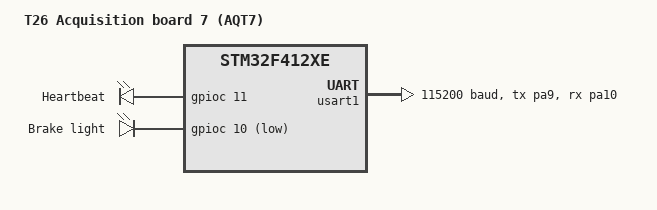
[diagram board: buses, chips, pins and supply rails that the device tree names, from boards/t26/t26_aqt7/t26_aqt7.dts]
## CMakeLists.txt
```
cmake_minimum_required(VERSION 3.20.0)

# The t26_aqt7 board lives in this folder (boards/t26/t26_aqt7).
# Zephyr doesn't search the application folder for boards on its own, so add it here.
list(APPEND BOARD_ROOT ${CMAKE_CURRENT_SOURCE_DIR})

# Default board when none is given (west build without -b, CLion "Let CMake decide").
# The board isn't in Zephyr's own board list, so IDE board pickers don't show it.
# A -b / BOARD given on the command line still takes precedence.
set(BOARD t26_aqt7 CACHE STRING "Zephyr board")

find_package(Zephyr REQUIRED HINTS $ENV{ZEPHYR_BASE})
project(t26_aqt7)

# Repository root: shared code used by both the STM32CubeIDE and the Zephyr builds
set(REPO_DIR ${CMAKE_CURRENT_SOURCE_DIR}/..)

target_sources(app PRIVATE
  src/main.c
  src/conversions.c
  src/sensors.c
  src/brake_light.c
  src/can_bus.c
  src/can_rx.c
  src/can_tx.c
  src/watchdog.c
  src/debug.c
  # cantools output, updated by the DBC workflow: never edit, only reference
  ${REPO_DIR}/Core/DBC/data_t26.c
  ${REPO_DIR}/Core/DBC/autonomous_t26.c
)

# "sim" shell command (CONFIG_AQT7_SIM, on by default when the shell is on)
target_sources_ifdef(CONFIG_AQT7_SIM app PRIVATE src/sim.c)

target_include_directories(app PRIVATE
  ${REPO_DIR}/Core/DBC
)
```

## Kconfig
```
# Application options for the AQT7 firmware. Set them in prj.conf.

mainmenu "T26 AQT7"

config AQT7_DEBUG_PRINT_MS
	int "Period of the sensor values log (ms), 0 = off"
	default 100
	help
	  The debug thread logs the brake pressures, suspensions and NTC with
	  their ADC values on the console every this many milliseconds, like
	  execute_100ms_tasks() in the STM32CubeIDE firmware. 0 turns it off;
	  the acq7 debug snapshot is updated either way.

source "Kconfig.zephyr"
```

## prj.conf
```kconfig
# GPIO: heartbeat (PC11) and brake light (PC10)
CONFIG_GPIO=y

# ADC1 (brake pressure, suspension, NTC) and CAN1/CAN2 drivers
CONFIG_ADC=y
CONFIG_CAN=y
# Error counters per type (stuff, form, ACK, bit, CRC) for can_bus_service()
CONFIG_STATS=y
CONFIG_CAN_STATS=y

# IWDG (watchdog0)
CONFIG_WATCHDOG=y
# sys_reboot(), used if a module fails to start and the IWDG isn't running
CONFIG_REBOOT=y

# Logging over the console (USART1, 115200 8N1)
CONFIG_LOG=y
CONFIG_LOG_DEFAULT_LEVEL=3
# %f in LOG_* / printk (sensor values in bar, mm, C)
CONFIG_CBPRINTF_FP_SUPPORT=y

# Use the Cortex-M4F hardware FPU for the sensor maths
CONFIG_FPU=y

# Sensor values log period (ms), like the CubeIDE 100 ms printf. 0 = off (acq7 still updated)
CONFIG_AQT7_DEBUG_PRINT_MS=100
```

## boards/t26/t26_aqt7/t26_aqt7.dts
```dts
/*
 * T26 Acquisition board 7 (AQT7)
 * MCU: STM32F412RET6 (512 KB Flash, 256 KB RAM, LQFP64)
 *
 * Pins and clocks follow T26_Acquisition_7.ioc (read-only reference).
 * Only clocks, console and the two outputs are described so far.
 * ADC1, CAN1, CAN2 and IWDG are added as they are ported.
 */

/dts-v1/;
#include <st/f4/stm32f412Xe.dtsi>
#include <st/f4/stm32f412r(e-g)tx-pinctrl.dtsi>

/ {
	model = "T26 Acquisition board 7 (AQT7)";
	compatible = "t26,aqt7";

	chosen {
		zephyr,console = &usart1;
		zephyr,shell-uart = &usart1;
		zephyr,sram = &sram0;
		zephyr,flash = &flash0;
	};

	leds: leds {
		compatible = "gpio-leds";

		/* PC11, toggled by the firmware to show the main loop is alive */
		heartbeat: heartbeat {
			gpios = <&gpioc 11 GPIO_ACTIVE_HIGH>;
			label = "Heartbeat";
		};

		/* PC10, active low: the pin is driven LOW to turn the brake light on.
		 * With GPIO_ACTIVE_LOW, gpio_pin_set_dt(..., 1) means "light on".
		 */
		brake_light: brake_light {
			gpios = <&gpioc 10 GPIO_ACTIVE_LOW>;
			label = "Brake light";
		};
	};

	aliases {
		led0 = &heartbeat;	/* lets samples/basic/blinky run unmodified */
		heartbeat = &heartbeat;
		brake-light = &brake_light;
	};
};

/* LSI: clock for the IWDG (watchdog), to be enabled when it is ported */
&clk_lsi {
	status = "okay";
};

/* No crystal on the board: HSI 16 MHz, same as the CubeIDE firmware */
&clk_hsi {
	status = "okay";
};

/* 16 MHz / 8 * 96 = 192 MHz VCO, /2 = 96 MHz SYSCLK, /4 = 48 MHz (Q, unused) */
&pll {
	div-m = <8>;
	mul-n = <96>;
	div-p = <2>;
	div-q = <4>;
	clocks = <&clk_hsi>;
	status = "okay";
};

/* SYSCLK 96 MHz, APB1 48 MHz (CAN), APB2 96 MHz (ADC, USART1) */
&rcc {
	clocks = <&pll>;
	clock-frequency = <DT_FREQ_M(96)>;
	ahb-prescaler = <1>;
	apb1-prescaler = <2>;
	apb2-prescaler = <1>;
};

&usart1 {
	pinctrl-0 = <&usart1_tx_pa9 &usart1_rx_pa10>;
	pinctrl-names = "default";
	current-speed = <115200>;
	status = "okay";
};
```

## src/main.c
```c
/*
 * T26 Acquisition board 7 (AQT7), Zephyr port.
 * Based on "original" C code
 *
 * main starts the IWDG, sets up the hardware in order, starts each module's thread, then runs
 * the heartbeat and feeds the watchdog while every thread is alive.
 *
 * Every module is required, like in the CubeIDE firmware: if one fails to set up, watchdog_fail()
 * stops feeding and the board resets after 2 s and tries the whole setup again
 * (the CubeIDE firmware did the same through Error_Handler + IWDG).
 */

#include <zephyr/kernel.h>
#include <zephyr/drivers/gpio.h>
#include <zephyr/logging/log.h>

#include "brake_light.h"
#include "can_bus.h"
#include "can_rx.h"
#include "can_tx.h"
#include "debug.h"
#include "sensors.h"
#include "watchdog.h"

LOG_MODULE_REGISTER(aqt7, LOG_LEVEL_INF);

#define HEARTBEAT_PERIOD_MS 100

static const struct gpio_dt_spec heartbeat = GPIO_DT_SPEC_GET(DT_ALIAS(heartbeat), gpios);

int main(void) {
    LOG_INF("T26 AQT7 starting on %s", CONFIG_BOARD);

    /* First, so a hang anywhere in the setup below also resets the board.
     * If it fails the board still runs, unprotected: that is better than not running at all.
     */
    if (watchdog_init() < 0) {
        LOG_ERR("IWDG not running: the board will NOT reset on a hang");
    }

    if (!gpio_is_ready_dt(&heartbeat) || gpio_pin_configure_dt(&heartbeat, GPIO_OUTPUT_INACTIVE) < 0) {
        watchdog_fail("heartbeat GPIO setup failed");
    }

    // ADC1: brake pressure, suspension, NTC
    if (sensors_init() < 0) {
        watchdog_fail("ADC setup failed");
    }

    // PC10 brake light
    if (brake_light_init() < 0) {
        watchdog_fail("brake light setup failed");
    }

    // Both CAN buses: start + RX filters
    if (can_bus_init(can_rx_ids, can_rx_id_count) < 0) {
        watchdog_fail("CAN setup failed");
    }

    // All hardware ready: start the threads (each registers with the watchdog)
    sensors_start();
    brake_light_start();
    can_rx_start();
    can_tx_start();
    debug_start();

    /* Absolute deadlines: the period doesn't drift with the time spent in the loop */
    int64_t next = k_uptime_get();

    while (1) {
        gpio_pin_toggle_dt(&heartbeat);
        watchdog_service();
        can_bus_service(); /* bus health, error log, restart of a stopped controller */

        next += HEARTBEAT_PERIOD_MS;
        k_sleep(K_TIMEOUT_ABS_MS(next));
    }

    return 0;
}
```

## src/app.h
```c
/*
 * Application-wide settings shared by the modules.
 */

#ifndef T26_AQT7_APP_H_
#define T26_AQT7_APP_H_

/*
 * Thread priorities: lower number = runs first (all preemptible).
 * Every thread is defined with SYS_FOREVER_MS as start delay, so it is created at boot but only
 * runs once main calls its module's *_start(), after the hardware it needs is set up.
 */
#define PRIO_SENSORS     2
#define PRIO_BRAKE_LIGHT 3
#define PRIO_CAN_RX      4
#define PRIO_CAN_TX      5
#define PRIO_DEBUG       6  /* lowest: snapshot and log only use spare CPU time */

#define STACK_SIZE_DEFAULT 1024
#define STACK_SIZE_DEBUG   2048 /* float formatting in the log */

#endif /* T26_AQT7_APP_H_ */
```

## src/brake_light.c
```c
/*
 * Brake light: PC10, driven from the rear (ADC) and front (CAN1 0x710) brake pressures.
 */

#include <zephyr/kernel.h>
#include <zephyr/drivers/gpio.h>
#include <zephyr/logging/log.h>

#include "app.h"
#include "watchdog.h"
#include "brake_light.h"
#include "can_rx.h"
#include "sensors.h"

LOG_MODULE_REGISTER(brake_light, LOG_LEVEL_INF);

#define BRAKE_LIGHT_PERIOD_MS 50
#define PRESSURE_LEVEL_REAR 7
#define PRESSURE_LEVEL_FRONT 7

static const struct gpio_dt_spec brake_light = GPIO_DT_SPEC_GET(DT_ALIAS(brake_light), gpios);

int brake_light_init(void) {
    if (!gpio_is_ready_dt(&brake_light)) {
        LOG_ERR("Brake light GPIO not ready");
        return -ENODEV;
    }

    /* Inactive = light off. The pin is active low in the devicetree, so this drives PC10 HIGH.
     * (The CubeIDE firmware boots with PC10 LOW, i.e. light on until the first 50 ms task.)
     */
    return gpio_pin_configure_dt(&brake_light, GPIO_OUTPUT_INACTIVE);
}

/**
 * Brake Light Thread
 * @param p1 UNUSED
 * @param p2 UNUSED
 * @param p3 UNUSED
 */
static void brake_light_thread(void *p1, void *p2, void *p3) {
    ARG_UNUSED(p1);
    ARG_UNUSED(p2);
    ARG_UNUSED(p3);

    while (1) {
        watchdog_checkin(WDOG_BRAKE_LIGHT);

        bool is_on = sensors_get().rear_brake_bar >= PRESSURE_LEVEL_REAR
                     || get_front_brake_pressure() >= PRESSURE_LEVEL_FRONT;

        gpio_pin_set_dt(&brake_light, is_on);

        k_sleep(K_MSEC(BRAKE_LIGHT_PERIOD_MS));
    }
}

K_THREAD_DEFINE(brakelight_tid, STACK_SIZE_DEFAULT, brake_light_thread, NULL, NULL, NULL,
                PRIO_BRAKE_LIGHT, 0, SYS_FOREVER_MS);

void brake_light_start(void) {
    watchdog_register(WDOG_BRAKE_LIGHT);
    k_thread_start(brakelight_tid);
}
```

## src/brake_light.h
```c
/*
 * Brake light output (PC10, active low).
 */

#ifndef T26_AQT7_BRAKE_LIGHT_H_
#define T26_AQT7_BRAKE_LIGHT_H_

/**
 * Configures PC10 as an output, light off.
 * @return 0 on success, negative errno otherwise
 */
int brake_light_init(void);

/* Starts the brake light thread. Call after brake_light_init() succeeded. */
void brake_light_start(void);

#endif /* T26_AQT7_BRAKE_LIGHT_H_ */
```

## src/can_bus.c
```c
/*
 * Both CAN controllers: start, RX filters, RX queue, non-blocking send, statistics.
 */

#include <string.h>
#include <zephyr/kernel.h>
#include <zephyr/device.h>
#include <zephyr/drivers/can.h>
#include <zephyr/logging/log.h>

#include "can_bus.h"

LOG_MODULE_REGISTER(can_bus, LOG_LEVEL_INF);

static const struct device *const can_dev[CAN_BUS_COUNT] = {
    [CAN_BUS_AUTONOMOUS] = DEVICE_DT_GET(DT_ALIAS(can_autonomous)),
    [CAN_BUS_DATA] = DEVICE_DT_GET(DT_ALIAS(can_data)),
};

static const char *const bus_names[CAN_BUS_COUNT] = {
    [CAN_BUS_AUTONOMOUS] = "Autonomous (CAN1)",
    [CAN_BUS_DATA] = "DATA (CAN2)",
};

/* Filled by the RX callback (ISR), emptied by can_bus_receive() in the RX thread */
#define CAN_RX_QUEUE_LEN 16
K_MSGQ_DEFINE(can_rx_q, sizeof(struct can_rx_msg), CAN_RX_QUEUE_LEN, 4);

struct can_bus_stats can_stats[CAN_BUS_COUNT];

const char *can_bus_name(enum can_bus bus) {
    return (bus < CAN_BUS_COUNT) ? bus_names[bus] : "?";
}

/* RX filter callback, runs in the CAN interrupt: only queue the frame, decode in the RX thread */
static void can_rx_callback(const struct device *dev, struct can_frame *frame, void *user_data) {
    ARG_UNUSED(dev);
    enum can_bus bus = (enum can_bus) (uintptr_t) user_data;
    struct can_rx_msg msg = {.bus = bus, .frame = *frame};

    if (k_msgq_put(&can_rx_q, &msg, K_NO_WAIT) == 0) {
        atomic_inc(&can_stats[bus].rx);
    } else {
        atomic_inc(&can_stats[bus].rx_dropped);
    }
}

/* TX done callback, runs in the CAN interrupt: error 0 = acknowledged */
static void can_tx_callback(const struct device *dev, int error, void *user_data) {
    ARG_UNUSED(dev);
    enum can_bus bus = (enum can_bus) (uintptr_t) user_data;

    if (error == 0) {
        atomic_inc(&can_stats[bus].tx_ok);
    } else {
        atomic_inc(&can_stats[bus].tx_error);
    }
}

/* Meaning and usual causes (same texts as the CubeIDE firmware) */
static const char *const can_state_name[] = {
    [CAN_STATE_ERROR_ACTIVE] = "OK - error active, bus healthy",
    [CAN_STATE_ERROR_WARNING] = "WARNING - TEC or REC >= 96: errors happening, still communicating",
    [CAN_STATE_ERROR_PASSIVE] = "PASSIVE - TEC or REC >= 128: many errors (REC high = receive side, TEC high = our TX side)",
    [CAN_STATE_BUS_OFF] = "BUS-OFF - TEC > 255: not sending, hardware recovers after 128 x 11 recessive bits",
    [CAN_STATE_STOPPED] = "STOPPED - controller off (start failed: bus stuck dominant, transceiver unpowered), restarting",
};

static const char *const can_error_name[CAN_ERROR_TYPE_COUNT] = {
    [CAN_ERROR_NONE] = "none",
    [CAN_ERROR_STUFF] = "STUFF - 6 equal bits: node at another bitrate, noise, missing 120R termination",
    [CAN_ERROR_FORM] = "FORM - fixed bit field wrong: bitrate or sample point mismatch, noise",
    [CAN_ERROR_ACK] = "ACK - nobody acknowledged our frame: no other node powered/connected, CANH/CANL open or swapped, other bitrate",
    [CAN_ERROR_BIT_RECESSIVE] = "BIT RECESSIVE - sent 1 read 0: bus held dominant or shorted, faulty node/transceiver",
    [CAN_ERROR_BIT_DOMINANT] = "BIT DOMINANT - sent 0 read 1: our TX not reaching the bus (transceiver off/standby, TX wiring)",
    [CAN_ERROR_CRC] = "CRC - corrupted frame: noise, bad termination or long stubs, bitrate mismatch",
    [CAN_ERROR_RX_OVERRUN] = "RX OVERRUN - receive FIFO full: frames arrive faster than they are read",
};

const char *can_bus_state_text(enum can_state state) {
    return (state < ARRAY_SIZE(can_state_name)) ? can_state_name[state] : "?";
}

const char *can_bus_error_text(enum can_error_type error) {
    return (error < CAN_ERROR_TYPE_COUNT) ? can_error_name[error] : "?";
}

/* One per bus; must not live on the stack (the driver keeps a pointer to it) */
static struct can_state_change_callback can_state_cb[CAN_BUS_COUNT];

static atomic_t bus_off_count[CAN_BUS_COUNT];

/* Runs in the CAN interrupt: only counts bus-off entries. Logging is done (rate limited) by
 * can_bus_service(). Bus-off is recovered automatically by the driver.
 */
static void can_state_callback(const struct device *dev, struct can_state_change_callback *cb,
                               enum can_state state, struct can_bus_err_cnt err_cnt) {
    ARG_UNUSED(dev);
    ARG_UNUSED(err_cnt);
    enum can_bus bus = (enum can_bus) (cb - can_state_cb); /* which entry of can_state_cb[] */

    if (state == CAN_STATE_BUS_OFF) {
        atomic_inc(&bus_off_count[bus]);
    }
}

int can_bus_init(const struct can_rx_id *rx_ids, size_t rx_id_count) {
    for (int bus = 0; bus < CAN_BUS_COUNT; bus++) {
        const struct device *dev = can_dev[bus];

        if (!device_is_ready(dev)) {
            LOG_ERR("%s not ready", can_bus_name(bus));
            return -ENODEV;
        }

        can_init_state_change_callback(&can_state_cb[bus], can_state_callback);
        int ret = can_add_state_change_callback(dev, &can_state_cb[bus]);
        if (ret < 0) {
            LOG_WRN("%s state callback not installed (%d)", can_bus_name(bus), ret);
        }

        ret = can_start(dev);
        if (ret < 0) {
            LOG_ERR("%s start failed (%d)", can_bus_name(bus), ret);
            return ret;
        }
    }

    for (size_t i = 0; i < rx_id_count; i++) {
        const struct can_filter filter = {
            .id = rx_ids[i].id,
            .mask = CAN_STD_ID_MASK, /* exact ID */
            .flags = 0,              /* standard ID, data frames */
        };
        enum can_bus bus = rx_ids[i].bus;

        int ret = can_add_rx_filter(can_dev[bus], can_rx_callback, (void *) (uintptr_t) bus, &filter);
        if (ret < 0) {
            LOG_ERR("%s filter 0x%03x failed (%d)", can_bus_name(bus), rx_ids[i].id, ret);
            return ret;
        }
    }

    return 0;
}

int can_send_frame(enum can_bus bus, uint32_t id, const uint8_t *data, uint8_t len) {
    struct can_frame frame = {
        .id = id,
        .dlc = can_bytes_to_dlc(len),
        .flags = 0,
    };
    memcpy(frame.data, data, len);

    int ret = can_send(can_dev[bus], &frame, K_NO_WAIT, can_tx_callback, (void *) (uintptr_t) bus);
    if (ret < 0) {
        /* -EAGAIN mailboxes full, -ENETUNREACH bus-off, -ENETDOWN stopped */
        atomic_inc(&can_stats[bus].tx_dropped);
    }
    return ret;
}

int can_bus_receive(struct can_rx_msg *msg, k_timeout_t timeout) {
    return k_msgq_get(&can_rx_q, msg, timeout);
}

/* ---------------------------------------------------------------------------------------------
 * Bus health (port of CAN_Service)
 * ------------------------------------------------------------------------------------------- */

#define CAN_RESTART_MS 100  /* min time between restarts of a stopped controller */
#define CAN_REPORT_MS 1000  /* log rate limit per bus */

static struct can_bus_status bus_status[CAN_BUS_COUNT];
K_MUTEX_DEFINE(bus_status_lock);

/* Driver counters reset on every can_start(): totals since boot = base + driver counter */
static uint32_t error_base[CAN_BUS_COUNT][CAN_ERROR_TYPE_COUNT];
static int64_t last_restart_ms[CAN_BUS_COUNT];
static int64_t last_report_ms[CAN_BUS_COUNT];
static enum can_state reported_state[CAN_BUS_COUNT];       /* zero = CAN_STATE_ERROR_ACTIVE */
static enum can_error_type reported_error[CAN_BUS_COUNT];  /* zero = CAN_ERROR_NONE */

/* Error counters kept by the driver (CONFIG_CAN_STATS), since the last can_start() */
static void read_driver_errors(const struct device *dev, uint32_t out[CAN_ERROR_TYPE_COUNT]) {
    memset(out, 0, sizeof(uint32_t) * CAN_ERROR_TYPE_COUNT);
#ifdef CONFIG_CAN_STATS
    out[CAN_ERROR_STUFF] = can_stats_get_stuff_errors(dev);
    out[CAN_ERROR_FORM] = can_stats_get_form_errors(dev);
    out[CAN_ERROR_ACK] = can_stats_get_ack_errors(dev);
    out[CAN_ERROR_BIT_RECESSIVE] = can_stats_get_bit1_errors(dev);
    out[CAN_ERROR_BIT_DOMINANT] = can_stats_get_bit0_errors(dev);
    out[CAN_ERROR_CRC] = can_stats_get_crc_errors(dev);
    out[CAN_ERROR_RX_OVERRUN] = can_stats_get_rx_overruns(dev);
#else
    ARG_UNUSED(dev);
#endif
}

void can_bus_service(void) {
    int64_t now = k_uptime_get();

    for (int bus = 0; bus < CAN_BUS_COUNT; bus++) {
        const struct device *dev = can_dev[bus];

        k_mutex_lock(&bus_status_lock, K_FOREVER);
        struct can_bus_status s = bus_status[bus];
        k_mutex_unlock(&bus_status_lock);

        enum can_state state;
        struct can_bus_err_cnt err_cnt;
        if (can_get_state(dev, &state, &err_cnt) < 0) {
            continue;
        }
        s.state = state;
        s.tec = err_cnt.tx_err_cnt;
        s.rec = err_cnt.rx_err_cnt;

        /* Error totals; the type that grew the most since the last call becomes last_error */
        uint32_t driver[CAN_ERROR_TYPE_COUNT];
        read_driver_errors(dev, driver);

        enum can_error_type newest = CAN_ERROR_NONE;
        uint32_t newest_inc = 0;
        for (int t = CAN_ERROR_NONE + 1; t < CAN_ERROR_TYPE_COUNT; t++) {
            uint32_t total = error_base[bus][t] + driver[t];
            uint32_t inc = total - s.errors[t];

            if (inc > newest_inc) {
                newest_inc = inc;
                newest = t;
            }
            s.errors[t] = total;
        }
        if (newest != CAN_ERROR_NONE) {
            s.last_error = newest;
            s.last_error_ms = (uint32_t) now;
        }

        s.bus_off_count = atomic_get(&bus_off_count[bus]);
        s.tx_ok = atomic_get(&can_stats[bus].tx_ok);
        s.tx_error = atomic_get(&can_stats[bus].tx_error);
        s.tx_dropped = atomic_get(&can_stats[bus].tx_dropped);
        s.rx = atomic_get(&can_stats[bus].rx);
        s.rx_dropped = atomic_get(&can_stats[bus].rx_dropped);

        /* Log a change of state or of the last error type, at most once per second */
        if (((s.state != reported_state[bus]) || (s.last_error != reported_error[bus])) &&
            ((now - last_report_ms[bus]) >= CAN_REPORT_MS)) {
            last_report_ms[bus] = now;
            reported_state[bus] = s.state;
            reported_error[bus] = s.last_error;

            /* Two lines: each stays under the 256-byte RTT message limit */
            if (s.state == CAN_STATE_ERROR_ACTIVE) {
                LOG_INF("%s %s | TEC=%u REC=%u", can_bus_name(bus),
                        can_bus_state_text(s.state), s.tec, s.rec);
                LOG_INF("%s last error: %s", can_bus_name(bus), can_bus_error_text(s.last_error));
            } else {
                LOG_WRN("%s %s | TEC=%u REC=%u", can_bus_name(bus),
                        can_bus_state_text(s.state), s.tec, s.rec);
                LOG_WRN("%s last error: %s", can_bus_name(bus), can_bus_error_text(s.last_error));
            }
        }

        /* Controller not running: restart it in place (filters are kept). Bus-off is not
         * included: the driver recovers from it by itself.
         */
        if ((s.state == CAN_STATE_STOPPED) && ((now - last_restart_ms[bus]) >= CAN_RESTART_MS)) {
            last_restart_ms[bus] = now;
            s.restarts++;

            /* can_start() resets the driver counters: keep the totals as the new base */
            memcpy(error_base[bus], s.errors, sizeof(error_base[bus]));

            int ret = can_start(dev);
            if (ret < 0) {
                LOG_WRN("%s restart failed (%d)", can_bus_name(bus), ret);
            }
        }

        k_mutex_lock(&bus_status_lock, K_FOREVER);
        bus_status[bus] = s;
        k_mutex_unlock(&bus_status_lock);
    }
}

struct can_bus_status can_bus_get_status(enum can_bus bus) {
    struct can_bus_status copy = {0};

    if (bus < CAN_BUS_COUNT) {
        k_mutex_lock(&bus_status_lock, K_FOREVER);
        copy = bus_status[bus];
        k_mutex_unlock(&bus_status_lock);
    }
    return copy;
}
```

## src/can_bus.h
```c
/*
 * Both CAN controllers: start, RX filters, RX queue, non-blocking send, statistics.
 * Knows nothing about the DBC: encoding is in can_tx.c, decoding in can_rx.c.
 */

#ifndef T26_AQT7_CAN_BUS_H_
#define T26_AQT7_CAN_BUS_H_

#include <stdint.h>
#include <zephyr/kernel.h>
#include <zephyr/drivers/can.h>

// The numbers here are not to be confused with any possible numeration given to the buses in other documentation
enum can_bus {
    CAN_BUS_AUTONOMOUS = 0, /* CAN1, PA11/PA12 (alias can-autonomous) */
    CAN_BUS_DATA,           /* CAN2, PB12/PB13 (alias can-data) */
    CAN_BUS_COUNT
};

/* A frame to receive: standard 11-bit ID, exact match. One hardware filter per entry. */
struct can_rx_id {
    enum can_bus bus;
    uint32_t id;
};

/* Received frame + the bus it came from */
struct can_rx_msg {
    enum can_bus bus;
    struct can_frame frame;
};

/* Per bus counters, for debugging (read them in the debugger or log them) */
struct can_bus_stats {
    atomic_t tx_ok;      /* frames acknowledged on the bus */
    atomic_t tx_error;   /* frames that failed after being queued (bus-off, stopped...) */
    atomic_t tx_dropped; /* not queued (mailboxes full, bus-off): the next period sends a fresh one */
    atomic_t rx;         /* frames received through the filters */
    atomic_t rx_dropped; /* RX queue full */
};

extern struct can_bus_stats can_stats[CAN_BUS_COUNT];

/* Protocol error types, as reported by the controller (bxCAN last error code) */
enum can_error_type {
    CAN_ERROR_NONE = 0,
    CAN_ERROR_STUFF,
    CAN_ERROR_FORM,
    CAN_ERROR_ACK,
    CAN_ERROR_BIT_RECESSIVE,
    CAN_ERROR_BIT_DOMINANT,
    CAN_ERROR_CRC,
    CAN_ERROR_RX_OVERRUN,
    CAN_ERROR_TYPE_COUNT
};

/* Health of one bus, refreshed by can_bus_service() (port of CAN_Service / CAN_BusStatus) */
struct can_bus_status {
    enum can_state state;
    uint8_t tec;                             /* transmit error counter */
    uint8_t rec;                             /* receive error counter */
    uint32_t errors[CAN_ERROR_TYPE_COUNT];   /* errors of each type since boot ([CAN_ERROR_NONE] unused) */
    enum can_error_type last_error;          /* most recent error type, CAN_ERROR_NONE if none yet */
    uint32_t last_error_ms;                  /* uptime of last_error */
    uint32_t bus_off_count;                  /* times the bus went bus-off */
    uint32_t restarts;                       /* controller restarts by can_bus_service() */
    uint32_t tx_ok, tx_error, tx_dropped, rx, rx_dropped; /* copies of can_stats[] */
};

/**
 * Call periodically (main does it every 100 ms). For each bus: reads the state, error counters
 * and error types; restarts a stopped controller (at most every 100 ms); logs a change of state
 * or of the last error type (at most once per second per bus).
 */
void can_bus_service(void);

/* Copy of the latest health of a bus, as refreshed by can_bus_service() */
struct can_bus_status can_bus_get_status(enum can_bus bus);

/* Readable texts for logs and the debugger */
const char *can_bus_state_text(enum can_state state);
const char *can_bus_error_text(enum can_error_type error);

/**
 * Starts both CAN controllers and installs one RX filter per entry of rx_ids.
 * Bitrate and sample point come from the devicetree. CAN_MODE_NORMAL retransmits until
 * acknowledged, like the CubeIDE firmware (AutoRetransmission = ENABLE).
 * @return 0 on success, negative errno otherwise
 */
int can_bus_init(const struct can_rx_id *rx_ids, size_t rx_id_count);

/**
 * Queues one standard-ID data frame. Never blocks: if every TX mailbox is busy the value is
 * dropped (counted) and the next period sends a fresh one, like the CubeIDE CAN_Send.
 * @return 0 if queued, negative errno otherwise
 */
int can_send_frame(enum can_bus bus, uint32_t id, const uint8_t *data, uint8_t len);

/**
 * Takes the next received frame (any bus) from the RX queue.
 * @return 0 on success, -EAGAIN on timeout
 */
int can_bus_receive(struct can_rx_msg *msg, k_timeout_t timeout);

/* Name for logs, e.g. "Autonomous (CAN1)" */
const char *can_bus_name(enum can_bus bus);

#endif /* T26_AQT7_CAN_BUS_H_ */
```

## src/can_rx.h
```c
/*
 * CAN receive: list of frames to read on both buses, decoding with the DBC code.
 */

#ifndef T26_AQT7_CAN_RX_H_
#define T26_AQT7_CAN_RX_H_

#include <stdbool.h>
#include <stddef.h>
#include <stdint.h>

#include "can_bus.h"

/* Frames to receive, passed to can_bus_init() */
extern const struct can_rx_id can_rx_ids[];
extern const size_t can_rx_id_count;

/* Starts the CAN RX thread. Call after can_bus_init() succeeded. */
void can_rx_start(void);

/**
 * @return Front brake pressure (CAN1 0x710) in bar, 0 if it never arrived or stopped arriving
 */
float get_front_brake_pressure(void);

/* Everything known about 0x710, for debugging */
struct front_brake_status {
    float bar;         /* same as get_front_brake_pressure() */
    uint16_t coded;    /* last FRT_BRK_PRESS received, 0.1 bar/bit (kept when 0x710 stops) */
    bool alive;        /* 0x710 arrived within the last 500 ms */
    uint32_t age_ms;   /* time since the last 0x710, UINT32_MAX if never received */
    uint32_t rx_count; /* 0x710 frames decoded since boot */
};

struct front_brake_status get_front_brake_status(void);

#endif /* T26_AQT7_CAN_RX_H_ */
```

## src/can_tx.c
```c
/*
 * CAN transmit: every periodic frame of both buses, each on its own absolute deadline.
 * To send a new frame: add a can_send_xxx() encoder and a next_xxx deadline in can_tx_thread.
 */

#include <string.h>
#include <zephyr/kernel.h>
#include <zephyr/spinlock.h>
#include <zephyr/sys/util.h>
#include <zephyr/logging/log.h>

#include "autonomous_t26.h"
#include "data_t26.h"

#include "app.h"
#include "watchdog.h"
#include "can_bus.h"
#include "can_tx.h"
#include "conversions.h"
#include "sensors.h"

LOG_MODULE_REGISTER(can_tx, LOG_LEVEL_INF);

#define CAN_AUTONOMOUS_AQT7_PERIOD_MS 50 /* CAN1 0x770, same as the CubeIDE firmware */
#define CAN_DATA_AQT7_PERIOD_MS 125      /* CAN2 0x770, 8 Hz */

/* Last payload passed to can_send_frame() for each frame, for debugging */
static struct can_tx_payloads last_payloads;
static struct k_spinlock last_payloads_lock;

struct can_tx_payloads can_tx_get_last_payloads(void) {
    k_spinlock_key_t key = k_spin_lock(&last_payloads_lock);
    struct can_tx_payloads copy = last_payloads;
    k_spin_unlock(&last_payloads_lock, key);
    return copy;
}

/* Autonomous bus (CAN1) 0x770 AQT7: rear brake pressure */
static void can_send_autonomous_aqt7(const struct vehicle_sensor_data *d) {
    struct autonomous_t26_aqt7_t msg = {
        .rear_brk_press = autonomous_t26_aqt7_rear_brk_press_encode(d->rear_brake_bar),
    };
    uint8_t data[AUTONOMOUS_T26_AQT7_LENGTH];

    if (autonomous_t26_aqt7_pack(data, &msg, sizeof(data)) < 0) {
        return;
    }

    k_spinlock_key_t key = k_spin_lock(&last_payloads_lock);
    memcpy(last_payloads.autonomous_aqt7, data, sizeof(data));
    k_spin_unlock(&last_payloads_lock, key);

    can_send_frame(CAN_BUS_AUTONOMOUS, AUTONOMOUS_T26_AQT7_FRAME_ID, data, sizeof(data));
}

/* DATA bus (CAN2) 0x770 AQT7: suspension and coolant temperature */
static void can_send_data_aqt7(const struct vehicle_sensor_data *d) {
    struct data_t26_aqt7_t msg = {
        .susp_l = data_t26_aqt7_susp_l_encode(d->susp_left_mm),
        .susp_r = data_t26_aqt7_susp_r_encode(d->susp_right_mm),
    };

    /* NTC_1 is uint8, 1 degC/bit: rounded and clamped to 0..254, 255 = open / shorted sensor */
    if (d->ntc1_c <= NTC_FAULT_C) {
        msg.ntc_1 = 255;
    } else {
        float t = CLAMP(d->ntc1_c, 0.0f, 254.0f);
        msg.ntc_1 = data_t26_aqt7_ntc_1_encode(t + 0.5f);
    }

    uint8_t data[DATA_T26_AQT7_LENGTH];

    if (data_t26_aqt7_pack(data, &msg, sizeof(data)) < 0) {
        return;
    }

    k_spinlock_key_t key = k_spin_lock(&last_payloads_lock);
    memcpy(last_payloads.data_aqt7, data, sizeof(data));
    k_spin_unlock(&last_payloads_lock, key);

    can_send_frame(CAN_BUS_DATA, DATA_T26_AQT7_FRAME_ID, data, sizeof(data));
}

/**
 * CAN TX Thread: sends every periodic frame of both buses, each on its own absolute deadline.
 */
static void can_tx_thread(void *p1, void *p2, void *p3) {
    ARG_UNUSED(p1);
    ARG_UNUSED(p2);
    ARG_UNUSED(p3);

    int64_t next_autonomous_aqt7 = k_uptime_get();
    int64_t next_data_aqt7 = next_autonomous_aqt7;

    while (1) {
        watchdog_checkin(WDOG_CAN_TX);

        int64_t now = k_uptime_get();
        struct vehicle_sensor_data d = sensors_get();

        if (now >= next_autonomous_aqt7) {
            can_send_autonomous_aqt7(&d);
            next_autonomous_aqt7 += CAN_AUTONOMOUS_AQT7_PERIOD_MS;
        }

        if (now >= next_data_aqt7) {
            can_send_data_aqt7(&d);
            next_data_aqt7 += CAN_DATA_AQT7_PERIOD_MS;
        }

        /* Add new periodic frames with their own next_* deadline and include it here */
        k_sleep(K_TIMEOUT_ABS_MS(MIN(next_autonomous_aqt7, next_data_aqt7)));
    }
}

K_THREAD_DEFINE(can_tx_tid, STACK_SIZE_DEFAULT, can_tx_thread, NULL, NULL, NULL,
                PRIO_CAN_TX, 0, SYS_FOREVER_MS);

void can_tx_start(void) {
    watchdog_register(WDOG_CAN_TX);
    k_thread_start(can_tx_tid);
}
```

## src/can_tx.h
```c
/*
 * CAN transmit: periodic frames of both buses, encoded with the DBC code.
 */

#ifndef T26_AQT7_CAN_TX_H_
#define T26_AQT7_CAN_TX_H_

#include <stdint.h>

#include "autonomous_t26.h"
#include "data_t26.h"

/* Last payload queued for each frame (port of acq7.can.tx_770_autonomous / tx_aqt7_data) */
struct can_tx_payloads {
    uint8_t autonomous_aqt7[AUTONOMOUS_T26_AQT7_LENGTH]; /* CAN1 0x770: rear brake pressure */
    uint8_t data_aqt7[DATA_T26_AQT7_LENGTH];             /* CAN2 0x770: SUSP_L, SUSP_R, NTC_1 */
};

/* Starts the CAN TX thread. Call after can_bus_init() succeeded. */
void can_tx_start(void);

/* Copy of the last payloads, for debugging */
struct can_tx_payloads can_tx_get_last_payloads(void);

#endif /* T26_AQT7_CAN_TX_H_ */
```

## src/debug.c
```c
/*
 * Debug snapshot (acq7) and periodic sensor log.
 * Port of Acq7_DebugUpdate() and execute_100ms_tasks() from the STM32CubeIDE firmware.
 * Only reads the other modules through their getters.
 */

#include <zephyr/kernel.h>
#include <zephyr/drivers/gpio.h>
#include <zephyr/logging/log.h>

#include "app.h"
#include "can_rx.h"
#include "debug.h"
#include "watchdog.h"

LOG_MODULE_REGISTER(debug, LOG_LEVEL_INF);

#define DEBUG_UPDATE_PERIOD_MS 10 /* same rate as Acq7_DebugUpdate() */

/* Not static: the debugger finds it by name */
struct acq7_debug acq7;

/* Read only: the pins are driven by brake_light.c and main.c */
static const struct gpio_dt_spec brake_light_pin = GPIO_DT_SPEC_GET(DT_ALIAS(brake_light), gpios);
static const struct gpio_dt_spec heartbeat_pin = GPIO_DT_SPEC_GET(DT_ALIAS(heartbeat), gpios);

static void debug_update(void) {
    struct vehicle_sensor_data acq7_data = sensors_get();
    struct front_brake_status front_brake_data = get_front_brake_status();

    acq7.time_ms = k_uptime_get_32();

    for (int i = 0; i < SENSOR_ADC_CHANNELS; i++) {
        acq7.adc.raw[i] = acq7_data.raw[i];
        acq7.adc.filtered[i] = acq7_data.filtered[i];
        acq7.adc.volts[i] = acq7_data.filtered[i] * 3.3f / 4095.0f;
    }

    acq7.sensors.brake_rear_bar = acq7_data.rear_brake_bar;
    acq7.sensors.brake_front_bar = front_brake_data.bar;
    acq7.sensors.susp_left_mm = acq7_data.susp_left_mm;
    acq7.sensors.susp_right_mm = acq7_data.susp_right_mm;
    acq7.sensors.ntc1_c = acq7_data.ntc1_c;

    /* Logical levels: brake_light 1 = on (the pin is active low) */
    acq7.io.brake_light = (uint8_t) gpio_pin_get_dt(&brake_light_pin);
    acq7.io.heartbeat = (uint8_t) gpio_pin_get_dt(&heartbeat_pin);

    acq7.front.coded = front_brake_data.coded;
    acq7.front.alive = front_brake_data.alive;
    acq7.front.age_ms = front_brake_data.age_ms;
    acq7.front.rx_count = front_brake_data.rx_count;

    acq7.can.tx = can_tx_get_last_payloads();
    acq7.can.autonomous = can_bus_get_status(CAN_BUS_AUTONOMOUS);
    acq7.can.data = can_bus_get_status(CAN_BUS_DATA);
}

/* Same content as the CubeIDE printf lines, from the snapshot just taken */
static void debug_print(void) {
    LOG_INF("Rear brake %.2f bar (adc %u) | Front brake %.2f bar (coded %u, %s)",
            (double) acq7.sensors.brake_rear_bar, acq7.adc.filtered[ADC_BRAKE],
            (double) acq7.sensors.brake_front_bar, acq7.front.coded,
            acq7.front.alive ? "alive" : "not arriving");
    LOG_INF("Susp L %.2f mm (adc %u) | Susp R %.2f mm (adc %u) | NTC1 %.1f C (adc %u)",
            (double) acq7.sensors.susp_left_mm, acq7.adc.filtered[ADC_SUSP_LEFT],
            (double) acq7.sensors.susp_right_mm, acq7.adc.filtered[ADC_SUSP_RIGHT],
            (double) acq7.sensors.ntc1_c, acq7.adc.filtered[ADC_NTC1]);
}

/**
 * Debug Thread: refreshes acq7 every 10 ms and logs the sensor values every
 * CONFIG_AQT7_DEBUG_PRINT_MS (0 = never). Lowest priority: it only uses spare CPU time.
 */
static void debug_thread(void *p1, void *p2, void *p3) {
    ARG_UNUSED(p1);
    ARG_UNUSED(p2);
    ARG_UNUSED(p3);

    int64_t next = k_uptime_get();
    int64_t next_print = next;

    while (1) {
        watchdog_checkin(WDOG_DEBUG);

        debug_update();

        if ((CONFIG_AQT7_DEBUG_PRINT_MS > 0) && (k_uptime_get() >= next_print)) {
            debug_print();
            next_print += CONFIG_AQT7_DEBUG_PRINT_MS;
        }

        next += DEBUG_UPDATE_PERIOD_MS;
        k_sleep(K_TIMEOUT_ABS_MS(next));
    }
}

K_THREAD_DEFINE(debug_tid, STACK_SIZE_DEBUG, debug_thread, NULL, NULL, NULL,
                PRIO_DEBUG, 0, SYS_FOREVER_MS);

void debug_start(void) {
    watchdog_register(WDOG_DEBUG);
    k_thread_start(debug_tid);
}
```

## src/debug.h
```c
/*
 * Debug snapshot (acq7) and periodic sensor log.
 *
 * acq7 is a global struct refreshed every 10 ms by the debug thread. Add "acq7" to a live view
 * (CLion Live Watches, STM32CubeIDE Live Expressions on zephyr.elf, STM32CubeMonitor) to watch the
 * whole board while it runs. Nothing in the firmware reads it.
 */

#ifndef T26_AQT7_DEBUG_H_
#define T26_AQT7_DEBUG_H_

#include <stdint.h>

#include "can_bus.h"
#include "can_tx.h"
#include "sensors.h"

struct acq7_debug {
    uint32_t time_ms;                         /* uptime (ms) */

    struct {
        uint16_t raw[SENSOR_ADC_CHANNELS];      /* latest samples: [0] PA7 brake, [1] PB0 susp L, [2] PB1 susp R, [3] PC4 NTC1 */
        uint16_t filtered[SENSOR_ADC_CHANNELS]; /* moving average */
        float volts[SENSOR_ADC_CHANNELS];       /* filtered value at the MCU pin (V) */
    } adc;

    struct {
        float brake_rear_bar;
        float brake_front_bar;                  /* 0 while 0x710 is not arriving */
        float susp_left_mm;
        float susp_right_mm;
        float ntc1_c;                           /* NTC_FAULT_C if open / shorted */
    } sensors;

    struct {
        uint8_t brake_light;                    /* 1 = light on (PC10 driven low) */
        uint8_t heartbeat;                      /* PC11 level */
    } io;

    struct {
        uint16_t coded;                         /* 0x710 FRT_BRK_PRESS, 0.1 bar/bit */
        uint8_t alive;                          /* 1 while 0x710 arrives within 500 ms */
        uint32_t age_ms;                        /* time since the last 0x710, UINT32_MAX if never */
        uint32_t rx_count;                      /* 0x710 frames received */
    } front;

    struct {
        struct can_tx_payloads tx;              /* last payloads queued on each bus */
        struct can_bus_status autonomous;       /* CAN1 */
        struct can_bus_status data;             /* CAN2 */
    } can;
};

/* The snapshot, at a fixed RAM address for the debugger */
extern struct acq7_debug acq7;

/* Starts the debug thread (snapshot every 10 ms, log every CONFIG_AQT7_DEBUG_PRINT_MS) */
void debug_start(void);

#endif /* T26_AQT7_DEBUG_H_ */
```

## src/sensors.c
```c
/*
 * ADC1 sampling: one sample of every channel each SAMPLE_PERIOD_MS, moving average of AVG_SAMPLES,
 * conversion to engineering units, suspension zeroing.
 */

#include <string.h>
#include <zephyr/kernel.h>
#include <zephyr/drivers/adc.h>
#include <zephyr/logging/log.h>

#include "app.h"
#include "watchdog.h"
#include "conversions.h"
#include "sensors.h"
#include "sim.h"

LOG_MODULE_REGISTER(sensors, LOG_LEVEL_INF);

/* Window = 10 ms * 10 = 100 ms. (The CubeIDE firmware sampled every 50 ms, a ~500 ms window.) */
#define SAMPLE_PERIOD_MS 10
#define AVG_SAMPLES 10

/* DT_FOREACH_PROP_ELEM passes (node_id, prop, idx); ADC_DT_SPEC_GET_BY_IDX only takes (node_id, idx) */
#define ADC_SPEC_AND_COMMA(node_id, prop, idx) ADC_DT_SPEC_GET_BY_IDX(node_id, idx),

/* Index order from zephyr,user in the dts: 0 brake pressure, 1 susp left, 2 susp right, 3 NTC */
static const struct adc_dt_spec ch[] = {
    DT_FOREACH_PROP_ELEM(DT_PATH(zephyr_user), io_channels, ADC_SPEC_AND_COMMA)
};

BUILD_ASSERT(ARRAY_SIZE(ch) == SENSOR_ADC_CHANNELS,
             "zephyr,user io-channels and enum sensor_channel are out of sync");

/* The STM32 driver returns one sample per channel, in channel number order (7, 8, 9, 14).
 * That matches the ch[] order, so raw_adc_data[i] belongs to ch[i].
 */
static uint16_t raw_adc_data[SENSOR_ADC_CHANNELS];
static struct adc_sequence seq = {
    .buffer = raw_adc_data,
    .buffer_size = sizeof(raw_adc_data),
};

static struct vehicle_sensor_data vehicle_data;
K_MUTEX_DEFINE(status_lock);

struct vehicle_sensor_data sensors_get(void) {
    k_mutex_lock(&status_lock, K_FOREVER);
    struct vehicle_sensor_data copy = vehicle_data;
    k_mutex_unlock(&status_lock);
    return copy;
}

int sensors_init(void) {
    for (size_t i = 0; i < SENSOR_ADC_CHANNELS; i++) {
        if (!adc_is_ready_dt(&ch[i])) {
            LOG_ERR("ADC %s not ready", ch[i].dev->name);
            return -ENODEV;
        }

        int ret = adc_channel_setup_dt(&ch[i]);
        if (ret < 0) {
            LOG_ERR("ADC channel %d setup failed (%d)", ch[i].channel_id, ret);
            return ret;
        }

        seq.channels |= BIT(ch[i].channel_id);
    }

    /* Resolution and oversampling come from the devicetree (12 bit) */
    return adc_sequence_init_dt(&ch[0], &seq);
}

/**
 * Sensors Thread: samples every ADC channel each SAMPLE_PERIOD_MS, filters with a moving average,
 * converts to engineering units and publishes the result in vehicle_data.
 */
static void sensor_sampling_thread(void *p1, void *p2, void *p3) {
    ARG_UNUSED(p1);
    ARG_UNUSED(p2);
    ARG_UNUSED(p3);

    // Moving average: circular buffer + running sum, so each update is O(channels)
    static uint16_t history[SENSOR_ADC_CHANNELS][AVG_SAMPLES];
    uint32_t sum[SENSOR_ADC_CHANNELS] = {0};
    uint16_t filtered[SENSOR_ADC_CHANNELS];
    uint8_t pos = 0;
    uint8_t count = 0; /* samples in the buffer, up to AVG_SAMPLES */

    // Ride height: the first full average is taken as 0 mm
    bool was_suspension_zeroed = false;
    float left_suspension_zero = 0.0f;
    float right_suspension_zero = 0.0f;

    int64_t next = k_uptime_get();

    while (1) {
        watchdog_checkin(WDOG_SENSORS);

        int ret = adc_read_dt(&ch[0], &seq);

        if (ret < 0) {
            LOG_WRN("ADC read failed (%d)", ret);
        } else {
            /* Channels overridden with the "sim" shell command replace the real sample */
            sim_apply(raw_adc_data);

            for (size_t channel = 0; channel < SENSOR_ADC_CHANNELS; channel++) {
                sum[channel] += raw_adc_data[channel];
                sum[channel] -= history[channel][pos];
                history[channel][pos] = raw_adc_data[channel];
            }

            // Next buffer position
            pos = (pos + 1) % AVG_SAMPLES;
            if (count < AVG_SAMPLES) {
                count++;
            }

            //Complete avg calculation
            for (size_t channel = 0; channel < SENSOR_ADC_CHANNELS; channel++) {
                filtered[channel] = (uint16_t) (sum[channel] / count);
            }

            float left_suspension_abs = MeasureSuspensionPosition(filtered[ADC_SUSP_LEFT]);
            float right_suspension_abs = MeasureSuspensionPosition(filtered[ADC_SUSP_RIGHT]);

            if (!was_suspension_zeroed && count == AVG_SAMPLES) {
                left_suspension_zero = left_suspension_abs;
                right_suspension_zero = right_suspension_abs;
                was_suspension_zeroed = true;
                LOG_INF("Suspension zeroed: L %.1f mm, R %.1f mm",
                        (double) left_suspension_zero, (double) right_suspension_zero);
            }

            // Sign convention (sent as SUSP_L / SUSP_R on the DATA bus):
            //   positive (+) = EXTENSION   (wheel drops, suspension opens past ride height)
            //   negative (-) = COMPRESSION (wheel rises, suspension closes past ride height)
            // The sensor voltage goes DOWN when the suspension extends on this car, hence ZERO - abs.
            struct vehicle_sensor_data data_sample = {
                .rear_brake_bar = MeasureBreakPressure(filtered[ADC_BRAKE]),
                .susp_left_mm = was_suspension_zeroed ? left_suspension_zero - left_suspension_abs : 0.0f,
                .susp_right_mm = was_suspension_zeroed ? right_suspension_zero - right_suspension_abs : 0.0f,
                .ntc1_c = MeasureNTCTemperature(filtered[ADC_NTC1]),
            };
            memcpy(data_sample.raw, raw_adc_data, sizeof(data_sample.raw));
            memcpy(data_sample.filtered, filtered, sizeof(data_sample.filtered));

            k_mutex_lock(&status_lock, K_FOREVER);
            vehicle_data = data_sample;
            k_mutex_unlock(&status_lock);
        }

        next += SAMPLE_PERIOD_MS;
        k_sleep(K_TIMEOUT_ABS_MS(next));
    }
}

K_THREAD_DEFINE(sensors_tid, STACK_SIZE_DEFAULT, sensor_sampling_thread, NULL, NULL, NULL,
                PRIO_SENSORS, 0, SYS_FOREVER_MS);

void sensors_start(void) {
    watchdog_register(WDOG_SENSORS);
    k_thread_start(sensors_tid);
}
```

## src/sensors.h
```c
/*
 * ADC1 sampling: brake pressure, suspension and coolant NTC.
 */

#ifndef T26_AQT7_SENSORS_H_
#define T26_AQT7_SENSORS_H_

#include <stdint.h>

/* Index of each signal in the zephyr,user io-channels list of the devicetree */
enum sensor_channel {
    ADC_BRAKE = 0,
    ADC_SUSP_LEFT = 1,
    ADC_SUSP_RIGHT = 2,
    ADC_NTC1 = 3,
    SENSOR_ADC_CHANNELS
};

/* Latest converted sensor values, written by the sensors thread */
struct vehicle_sensor_data {
    float rear_brake_bar;
    float susp_left_mm;  /* relative to ride height: + extension, - compression, 0 until zeroed */
    float susp_right_mm;
    float ntc1_c;        /* NTC_FAULT_C for an open or shorted sensor */
    uint16_t raw[SENSOR_ADC_CHANNELS];      /* latest sample per channel, ADC counts (for debugging) */
    uint16_t filtered[SENSOR_ADC_CHANNELS]; /* moving average per channel, ADC counts (for debugging) */
};

/**
 * Configures ADC1 and every channel.
 * @return 0 on success, negative errno otherwise
 */
int sensors_init(void);

/* Starts the sampling thread. Call after sensors_init() succeeded. */
void sensors_start(void);

/**
 * @return A consistent copy of the latest sensor values
 */
struct vehicle_sensor_data sensors_get(void);

#endif /* T26_AQT7_SENSORS_H_ */
```
